# ATSAM4LS8B device description
Architecture: CORTEX-M4; Family: SAM4; Series: SAM4L
Registers are 32-bit, read-write, reset 0x0 unless marked. A register's access mark holds for its fields unless they carry their own. Offsets are from the block's base; [hi:lo] are bit positions; {n}, {i} and the like mark numbered series.

## PEVC — Peripheral Event Controller
Instances: PEVC 0x400A6000
0x00 CHSR ro — Channel Status Register
  [31:0] CHS — Channel Status
    0=Channel j Disabled; 1=Channel j Enabled
0x04 CHER wo (atomic set of CHSR) — Channel Enable Register
  [31:0] CHE — Channel Enable
    0=No Action; 1=Enable Channel j
0x08 CHDR wo (atomic clear of CHSR) — Channel Disable Register
  [31:0] CHD — Channel Disable
    0=No Action; 1=Disable Channel j
0x10 SEV wo — Software Event
  [31:0] SEV
    0=No Action; 1=CPU forces software event to channel j
0x14 BUSY ro — Channel / User Busy
  [31:0] BUSY — Channel Status
    0=No Action; 1=Channel j or User j is Busy
0x20 TRIER wo (atomic set of TRIMR) — Trigger Interrupt Mask Enable Register
  [31:0] TRIE — Trigger Interrupt Enable
    0=No Action; 1=Enable Trigger j Interrupt
0x24 TRIDR wo (atomic clear of TRIMR) — Trigger Interrupt Mask Disable Register
  [31:0] TRID — Trigger Interrupt Disable
    0=No Action; 1=Disable Trigger j Interrupt
0x28 TRIMR ro — Trigger Interrupt Mask Register
  [31:0] TRIM — Trigger Interrupt Mask
    0=Trigger j Interrupt Disabled; 1=Trigger j Interrupt Enabled
0x30 TRSR ro — Trigger Status Register
  [31:0] TRS — Trigger Interrupt Status
    0=Channel j did not send out an Event in the past; 1=Channel j did send out an Event in the past
0x34 TRSCR wo (atomic clear of TRSR) — Trigger Status Clear Register
  [31:0] TRSC — Trigger Interrupt Status Clear
    0=No Action; 1=Clear TRSR[j]
0x40 OVIER wo (atomic set of OVIMR) — Overrun Interrupt Mask Enable Register
  [31:0] OVIE — Overrun Interrupt Enable
    0=No Action; 1=Enable Overrun Interrupt for Channel j
0x44 OVIDR wo (atomic clear of OVIMR) — Overrun Interrupt Mask Disable Register
  [31:0] OVID — Overrun Interrupt Disable
    0=No Action; 1=Enable Overrun Interrupt for Channel j
0x48 OVIMR ro — Overrun Interrupt Mask Register
  [31:0] OVIM — Overrun Interrupt Mask
    0=Overrun Interrupt for Channel j Disabled; 1=Overrun Interrupt for Channel j Enabled
0x50 OVSR ro — Overrun Status Register
  [31:0] OVS — Overrun Interrupt Status
    0=No Overrun occured on Channel j; 1=Overrun occured on Channel j
0x54 OVSCR wo (atomic clear of OVSR) — Overrun Status Clear Register
  [31:0] OVSC — Overrun Interrupt Status Clear
    0=No Action; 1=Clear Overrun Status Bit j
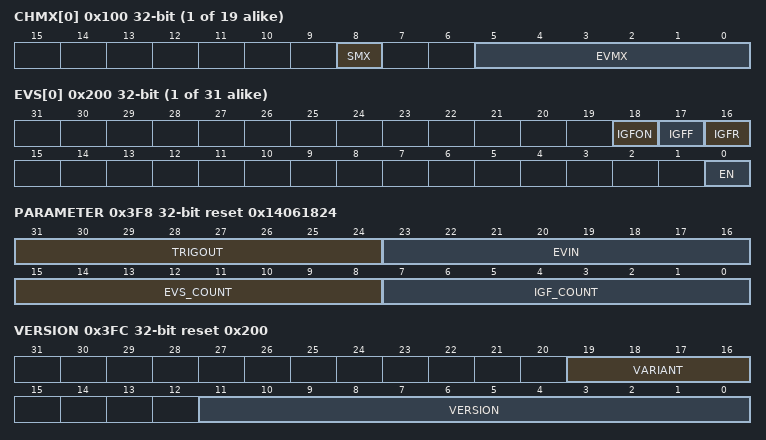
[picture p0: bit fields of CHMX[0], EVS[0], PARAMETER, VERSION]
{0x100+4i} CHMX[{i}] (i=0..18) — Channel Multiplexer
  [8] SMX — Software Event Multiplexer
    0=Hardware events; 1=Software event
  [5:0] EVMX — Event Multiplexer
    0=Event 0; 1=Event 1
{0x200+4i} EVS[{i}] (i=0..30) — Event Shaper
  [18] IGFON — Input Glitch Filter Status
  [17] IGFF — Input Glitch Filter Fall
    0=No Action; 1=Input Glitch Filter : a falling edge on event input will raise trigger output
  [16] IGFR — Input Glitch Filter Rise
    0=No Action; 1=Input Glitch Filter : a rising edge on event input will raise trigger output
  [0] EN — Event Shaper Enable
    0=No Action; 1=Event Shaper enable
0x300 IGFDR — Input Glitch Filter Divider Register
  [3:0] IGFDR
0x3F8 PARAMETER ro reset 0x14061824
  [31:24] TRIGOUT — Number of Trigger Outputs / Channels / Users
  [23:16] EVIN — Number of Event Inputs / Generators
  [15:8] EVS_COUNT — Number of Event Shapers
  [7:0] IGF_COUNT — Number of Input Glitch Filters
0x3FC VERSION ro reset 0x200
  [19:16] VARIANT — Variant Number
  [11:0] VERSION — Version Number

## PICOUART
Instances: PICOUART 0x400F1400
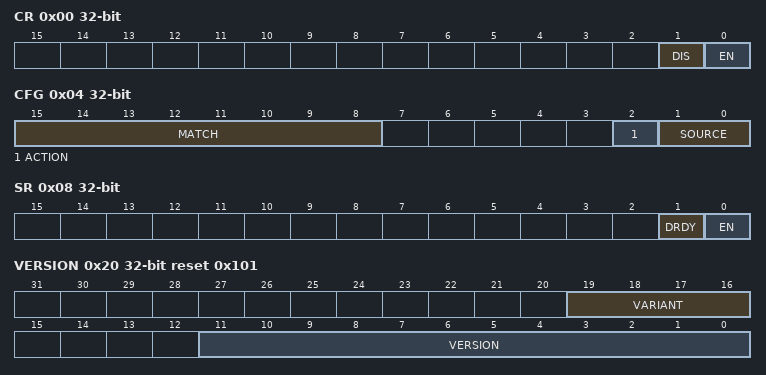
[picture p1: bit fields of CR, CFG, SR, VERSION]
0x00 CR wo — Control Register
  [1] DIS — Disable
  [0] EN — Enable
0x04 CFG — Configuration Register
  [15:8] MATCH — Data Match
  [2] ACTION — Action to perform
  [1:0] SOURCE — Source Enable Mode
0x08 SR ro — Status Register
  [1] DRDY — Data Ready Interrupt Status
  [0] EN — Enable Interrupt Status
0x0C RHR ro — Receive Holding Register
  [31:0] CDATA — Received Data
0x20 VERSION ro reset 0x101
  [19:16] VARIANT — Variant Number
  [11:0] VERSION — Version Number
